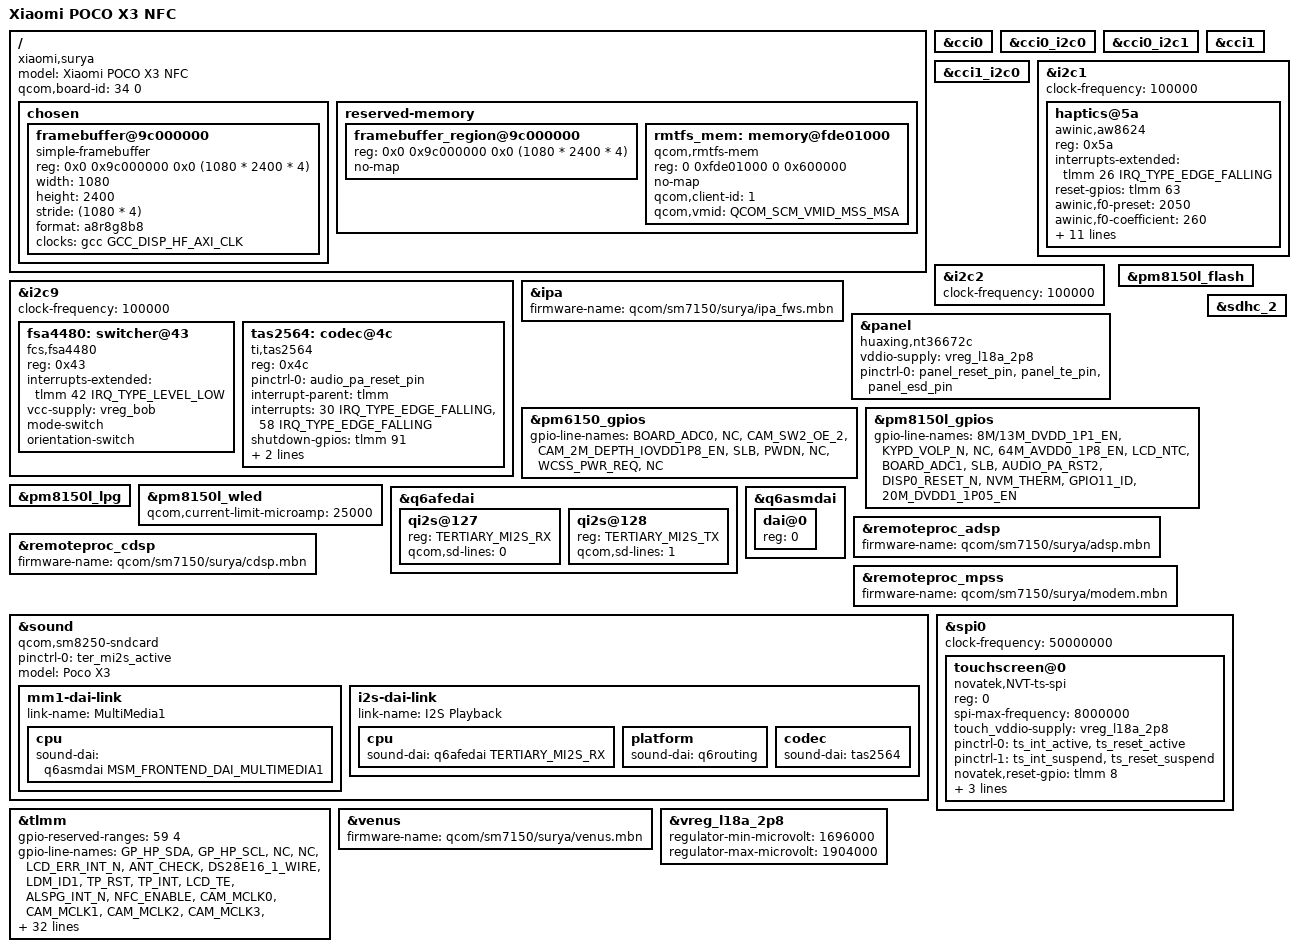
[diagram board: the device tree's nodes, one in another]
// SPDX-License-Identifier: BSD-3-Clause
/*
 * Copyright (c) 2023, Danila Tikhonov <danila@jiaxyga.com>
 * Copyright (c) 2023, David Wronek <davidwronek@gmail.com>
 */

/dts-v1/;

#include <dt-bindings/sound/qcom,q6asm.h>

#include "sm7150-xiaomi-common.dtsi"

/ {
	/*
	 * Xiaomi POCO X3 (karna)
	 * Xiaomi POCO X3 NFC (surya)
	 */
	model = "Xiaomi POCO X3 NFC";
	compatible = "xiaomi,surya", "qcom,sm7150";

	qcom,board-id = <34 0>;

	chosen {
		#address-cells = <2>;
		#size-cells = <2>;
		ranges;
		framebuffer@9c000000 {
			compatible = "simple-framebuffer";
			reg = <0x0 0x9c000000 0x0 (1080 * 2400 * 4)>;
			width = <1080>;
			height = <2400>;
			stride = <(1080 * 4)>;
			format = "a8r8g8b8";
			clocks = <&gcc GCC_DISP_HF_AXI_CLK>;
		};
	};

	reserved-memory {
		framebuffer_region@9c000000 {
			reg = <0x0 0x9c000000 0x0 (1080 * 2400 * 4)>;
			no-map;
		};

		/*
		 * The rmtfs memory region in downstream is 'dynamically allocated'
		 * but given the same address every time. Hard code it as this address is
		 * where the modem firmware expects it to be.
		 */
		rmtfs_mem: memory@fde01000 {
			compatible = "qcom,rmtfs-mem";
			reg = <0 0xfde01000 0 0x600000>;
			no-map;

			qcom,client-id = <1>;
			qcom,vmid = <QCOM_SCM_VMID_MSS_MSA>;
		};
	};
};

&cci0 {
	status = "okay";
};

&cci0_i2c0 {
	/* Sony IMX682 Main @ 50 */
};

&cci0_i2c1 {
	/* OmniVision ov02b1b Depth @ 50 */
};

&cci1 {
	status = "okay";
};

&cci1_i2c0 {
	/* Samsung S5K3T2 Front @ ? */
	/* Sk Hynix Hi-259 Macro @ ? */
	/* Sk Hynix Hi-1337 Ultrawide @ ? */
};

&i2c1 {
	clock-frequency = <100000>;
	status = "okay";

	haptics@5a {
		compatible = "awinic,aw8624";
		reg = <0x5a>;
		interrupts-extended = <&tlmm 26 IRQ_TYPE_EDGE_FALLING>;
		reset-gpios = <&tlmm 63 GPIO_ACTIVE_HIGH>;

		awinic,f0-preset = <2050>;
		awinic,f0-coefficient = <260>;
		awinic,f0-calibration-percent = <7>;
		awinic,drive-level = <100>;

		awinic,f0-detection-play-time = <9>;
		awinic,f0-detection-wait-time = <5>;
		awinic,f0-detection-repeat = <1>;
		awinic,f0-detection-trace = <15>;

		awinic,boost-debug = /bits/ 8 <0x1b 0x1b 0x16>; // ?
		awinic,tset = /bits/ 8 <0x11>;
		awinic,r-spare = /bits/ 8 <0x68>;

		awinic,bemf-upper-threshold = <4000>; // ?
		awinic,bemf-lower-threshold = <2500>; // ?
	};
};

&i2c2 {
	clock-frequency = <100000>;
	status = "okay";

	/* nqx,nq-nci nxp55303 (nfc) @ 28 */
};

&i2c9 {
	clock-frequency = <100000>;
	status = "okay";

	/* ovti,wl2866d (cam regulator) @ 28 */

	fsa4480: switcher@43 {
		compatible = "fcs,fsa4480";
		reg = <0x43>;

		interrupts-extended = <&tlmm 42 IRQ_TYPE_LEVEL_LOW>;

		vcc-supply = <&vreg_bob>;

		mode-switch;
		orientation-switch;
	};

	tas2564: codec@4c {
		compatible = "ti,tas2564";
		reg = <0x4c>;
		#sound-dai-cells = <0>;
		pinctrl-names = "default";
		pinctrl-0 = <&audio_pa_reset_pin>;
		interrupt-parent = <&tlmm>;
		interrupts = <30 IRQ_TYPE_EDGE_FALLING>,
			     <58 IRQ_TYPE_EDGE_FALLING>;
		shutdown-gpios = <&tlmm 91 GPIO_ACTIVE_HIGH>;
		ti,vmon-slot-no = <0>;
		ti,imon-slot-no = <0>;
	};

	/* ti,bq25968 (charger) @ 65 */
};

&ipa {
	firmware-name = "qcom/sm7150/surya/ipa_fws.mbn";
	status = "okay";
};

&panel {
	compatible = "huaxing,nt36672c";
	vddio-supply = <&vreg_l18a_2p8>;
	/delete-property/ vdd3p3-supply;
	pinctrl-0 = <&panel_reset_pin &panel_te_pin &panel_esd_pin>;
};

&pm6150_gpios {
	gpio-line-names = "BOARD_ADC0", /* GPIO_1 */
			  "NC",
			  "CAM_SW2_OE_2",
			  "CAM_2M_DEPTH_IOVDD1P8_EN",
			  "SLB",
			  "PWDN",
			  "NC",
			  "WCSS_PWR_REQ",
			  "NC";
};

&pm8150l_flash {
	status = "okay";
};

&pm8150l_gpios {
	gpio-line-names = "8M/13M_DVDD_1P1_EN", /* GPIO_1 */
			  "KYPD_VOLP_N",
			  "NC",
			  "64M_AVDD0_1P8_EN",
			  "LCD_NTC",
			  "BOARD_ADC1",
			  "SLB",
			  "AUDIO_PA_RST2",
			  "DISP0_RESET_N",
			  "NVM_THERM", /* GPIO_10 */
			  "GPIO11_ID",
			  "20M_DVDD1_1P05_EN";
};

&pm8150l_lpg {
	status = "okay";
};

&pm8150l_wled {
	qcom,current-limit-microamp = <25000>;
	status = "okay";
};

&q6afedai {
	qi2s@127 {
		reg = <TERTIARY_MI2S_RX>;
		qcom,sd-lines = <0>;
	};

	qi2s@128 {
		reg = <TERTIARY_MI2S_TX>;
		qcom,sd-lines = <1>;
	};
};

&q6asmdai {
	dai@0 {
		reg = <0>;
	};
};

&remoteproc_adsp {
	firmware-name = "qcom/sm7150/surya/adsp.mbn";
	status = "okay";
};

&remoteproc_cdsp {
	firmware-name = "qcom/sm7150/surya/cdsp.mbn";
	status = "okay";
};

&remoteproc_mpss {
	firmware-name = "qcom/sm7150/surya/modem.mbn";
	status = "okay";
};

&sdhc_2 {
	status = "okay";
};

&sound {
	compatible = "qcom,sm8250-sndcard";
	pinctrl-0 = <&ter_mi2s_active>;
	pinctrl-names = "default";
	model = "Poco X3";

	mm1-dai-link {
		link-name = "MultiMedia1";
		cpu {
			sound-dai = <&q6asmdai MSM_FRONTEND_DAI_MULTIMEDIA1>;
		};
	};

	i2s-dai-link {
		link-name = "I2S Playback";
		cpu {
			sound-dai = <&q6afedai TERTIARY_MI2S_RX>;
		};

		platform {
			sound-dai = <&q6routing>;
		};

		codec {
			sound-dai = <&tas2564>;
		};
	};
};

&spi0 {
	clock-frequency = <50000000>;
	status = "okay";

	touchscreen@0 {
		compatible = "novatek,NVT-ts-spi";
		reg = <0>;

		spi-max-frequency = <8000000>;

		touch_vddio-supply = <&vreg_l18a_2p8>;

		pinctrl-0 = <&ts_int_active &ts_reset_active>;
		pinctrl-1 = <&ts_int_suspend &ts_reset_suspend>;
		pinctrl-names = "default", "sleep";

		novatek,reset-gpio = <&tlmm 8 GPIO_ACTIVE_HIGH>;
		novatek,irq-gpio = <&tlmm 9 IRQ_TYPE_EDGE_FALLING>;

		/* 672C */
		novatek,swrst-n8-addr = <0x03f0fe>;
		novatek,spi-rd-fast-addr = <0x03f310>;
	};
};

&tlmm {
	gpio-reserved-ranges = <59 4>;

	gpio-line-names = "GP_HP_SDA", /* GPIO_0 */
			  "GP_HP_SCL",
			  "NC",
			  "NC",
			  "LCD_ERR_INT_N",
			  "ANT_CHECK",
			  "DS28E16_1_WIRE",
			  "LDM_ID1",
			  "TP_RST",
			  "TP_INT",
			  "LCD_TE", /* GPIO_10 */
			  "ALSPG_INT_N",
			  "NFC_ENABLE",
			  "CAM_MCLK0",
			  "CAM_MCLK1",
			  "CAM_MCLK2",
			  "CAM_MCLK3",
			  "CC_I2C_SDA0",
			  "CC_I2C_SCL0",
			  "CC_I2C_SDA1",
			  "CC_I2C_SCL1", /* GPIO_20 */
			  "CLK_BUFFER_2",
			  "NC",
			  "CAM4_RST_N",
			  "CAM3_RST_N",
			  "CAM1_RST_N",
			  "HAPTIC_INT_N",
			  "CC_I2C_SDA2",
			  "CC_I2C_SCL2",
			  "NC",
			  "AUDIO_INT1",  /* GPIO_30 */
			  "NFC_CLK_REQ",
			  "CLK_BUFFER_3",
			  "CLK_BUFFER_4",
			  "NFC_I2C_SDA",
			  "NFC_I2C_SCL",
			  "NFC_DWL_REQ",
			  "NFC_IRQ",
			  "BT_UART_CTS",
			  "BT_UART_RFR",
			  "BT_UART_TX", /* GPIO_40 */
			  "BT_UART_RX",
			  "SVDD_PWR_REQ",
			  "CHARGER_INT",
			  "DBG_UART_TX",
			  "DBG_UART_RX",
			  "AUDIO_I2C_SDA",
			  "AUDIO_I2C_SCL",
			  "FORCE_USB_BOOT",
			  "TS_SPI_MISO",
			  "TS_SPI_MOSI", /* GPIO_50 */
			  "TS_SPI_CLK",
			  "TS_SPI_CS_N",
			  "LPI_MI2S_1_SCK",
			  "LPI_MI2S_1_WS",
			  "LPI_MI2S_1_DATA0",
			  "LPI_MI2S_1_DATA1",
			  "CHIP_EN",
			  "AUDIO_INT2",
			  "FP_SPI_MISO",
			  "FP_SPI_MOSI", /* GPIO_60 */
			  "FP_SPI_CLK",
			  "FP_SPI_CS",
			  "HAPTIC_RST_N",
			  "CAM5_RST_N",
			  "DRV_VDD2P8_EN",
			  "64M_AF_EN",
			  "SAR_CAP_INI",
			  "CLK_BUFFER_1",
			  "SD_CARD_DET_N",
			  "NC", /* GPIO_70 */
			  "LDM_IDO",
			  "CAM0_RST_N",
			  "WLAN_SW_CTRL",
			  "PRX_TUNER_SW3",
			  "UIM2_DATA",
			  "UIM2_CLK",
			  "UIM2_RESET",
			  "UIM2_PRESENT",
			  "UIM1_DATA",
			  "UIM1_CLK", /* GPIO_80 */
			  "UIM1_RESET",
			  "UIM1_PRESENT",
			  "PRX_TUNER_SW1",
			  "ANT_CHECK_DIV",
			  "WMSS_RESET_N",
			  "GINT1",
			  "GINT2",
			  "8M_AFVDD_2P8_EN",
			  "FP_INT_N",
			  "FP_RESET_N", /* GPIO_90 */
			  "AUDIO_PA_RST1",
			  "NC",
			  "CAM2_RST_N",
			  "SWITCH_SEL1",
			  "DPDT_TUNER_SW",
			  "QLINK_REQUEST",
			  "QLINK_ENABLE",
			  "LNA_PRX_B1_EN",
			  "DRX_TUNER_SW4",
			  "DRX_ANT_EN", /* GPIO_100 */
			  "NC",
			  "IR_EN_SPI_MOSI",
			  "NC",
			  "USB_PHY_PS",
			  "RFFE5_DATA",
			  "RFFE5_CLK",
			  "LNA_DRX_B7B38B41_EN_v2",
			  "MSS_LTE_COXM_TXD",
			  "MSS_LTE_COXM_RXD",
			  "RFFE2_DATA", /* GPIO_110 */
			  "RFFE2_CLK",
			  "RFFE1_DATA",
			  "RFFE1_CLK";
};

&venus {
	firmware-name = "qcom/sm7150/surya/venus.mbn";
	status = "okay";
};

&vreg_l18a_2p8 {
	regulator-min-microvolt = <1696000>;
	regulator-max-microvolt = <1904000>;
};
